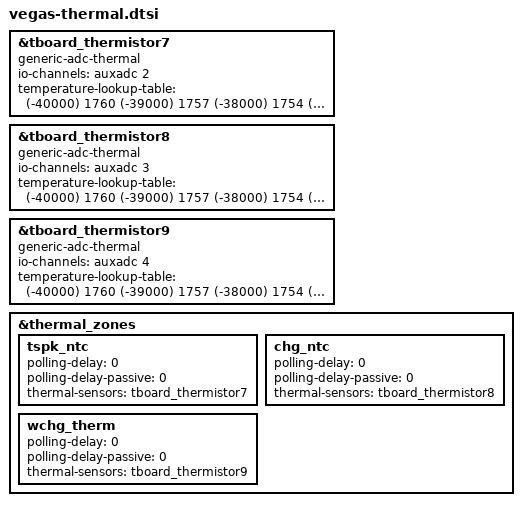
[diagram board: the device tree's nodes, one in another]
#include <dt-bindings/iio/mt635x-auxadc.h>

	&tboard_thermistor7 {
		compatible = "generic-adc-thermal";
		#thermal-sensor-cells = <0>;
		io-channels = <&auxadc 2>;
		io-channel-names = "sensor-channel";
		temperature-lookup-table = <
			(-40000) 1760
			(-39000) 1757
			(-38000) 1754
			(-37000) 1751
			(-36000) 1747
			(-35000) 1744
			(-34000) 1740
			(-33000) 1736
			(-32000) 1731
			(-31000) 1727
			(-30000) 1722
			(-29000) 1716
			(-28000) 1711
			(-27000) 1705
			(-26000) 1699
			(-25000) 1693
			(-24000) 1686
			(-23000) 1679
			(-22000) 1672
			(-21000) 1664
			(-20000) 1656
			(-19000) 1648
			(-18000) 1639
			(-17000) 1630
			(-16000) 1620
			(-15000) 1610
			(-14000) 1599
			(-13000) 1588
			(-12000) 1577
			(-11000) 1565
			(-10000) 1553
			(-9000) 1540
			(-8000) 1527
			(-7000) 1514
			(-6000) 1500
			(-5000) 1485
			(-4000) 1470
			(-3000) 1455
			(-2000) 1439
			(-1000) 1423
			0 1406
			1000 1389
			2000 1372
			3000 1354
			4000 1335
			5000 1317
			6000 1298
			7000 1279
			8000 1259
			9000 1239
			10000 1219
			11000 1198
			12000 1178
			13000 1157
			14000 1136
			15000 1115
			16000 1093
			17000 1072
			18000 1050
			19000 1029
			20000 1007
			21000 986
			22000 964
			23000 943
			24000 921
			25000 900
			26000 879
			27000 858
			28000 837
			29000 816
			30000 796
			31000 775
			32000 755
			33000 736
			34000 716
			35000 697
			36000 678
			37000 659
			38000 641
			39000 623
			40000 605
			41000 588
			42000 571
			43000 555
			44000 538
			45000 523
			46000 507
			47000 492
			48000 477
			49000 463
			50000 449
			51000 435
			52000 422
			53000 409
			54000 396
			55000 384
			56000 372
			57000 360
			58000 349
			59000 338
			60000 327
			61000 317
			62000 307
			63000 297
			64000 288
			65000 279
			66000 270
			67000 261
			68000 253
			69000 245
			70000 237
			71000 230
			72000 222
			73000 215
			74000 209
			75000 202
			76000 196
			77000 189
			78000 183
			79000 178
			80000 172
			81000 167
			82000 161
			83000 156
			84000 151
			85000 147
			86000 142
			87000 138
			88000 133
			89000 129
			90000 125
			91000 121
			92000 118
			93000 114
			94000 111
			95000 107
			96000 104
			97000 101
			98000 98
			99000 95
			100000 92
			101000 89
			102000 87
			103000 84
			104000 81
			105000 79
			106000 77
			107000 74
			108000 72
			109000 70
			110000 68
			111000 66
			112000 64
			113000 62
			114000 61
			115000 59
			116000 57
			117000 56
			118000 54
			119000 52
			120000 51
			121000 50
			122000 48
			123000 47
			124000 46
			125000 44>;
	};

	&tboard_thermistor8 {
		compatible = "generic-adc-thermal";
		#thermal-sensor-cells = <0>;
		io-channels = <&auxadc 3>;
		io-channel-names = "sensor-channel";
		temperature-lookup-table = <
			(-40000) 1760
			(-39000) 1757
			(-38000) 1754
			(-37000) 1751
			(-36000) 1747
			(-35000) 1744
			(-34000) 1740
			(-33000) 1736
			(-32000) 1731
			(-31000) 1727
			(-30000) 1722
			(-29000) 1716
			(-28000) 1711
			(-27000) 1705
			(-26000) 1699
			(-25000) 1693
			(-24000) 1686
			(-23000) 1679
			(-22000) 1672
			(-21000) 1664
			(-20000) 1656
			(-19000) 1648
			(-18000) 1639
			(-17000) 1630
			(-16000) 1620
			(-15000) 1610
			(-14000) 1599
			(-13000) 1588
			(-12000) 1577
			(-11000) 1565
			(-10000) 1553
			(-9000) 1540
			(-8000) 1527
			(-7000) 1514
			(-6000) 1500
			(-5000) 1485
			(-4000) 1470
			(-3000) 1455
			(-2000) 1439
			(-1000) 1423
			0 1406
			1000 1389
			2000 1372
			3000 1354
			4000 1335
			5000 1317
			6000 1298
			7000 1279
			8000 1259
			9000 1239
			10000 1219
			11000 1198
			12000 1178
			13000 1157
			14000 1136
			15000 1115
			16000 1093
			17000 1072
			18000 1050
			19000 1029
			20000 1007
			21000 986
			22000 964
			23000 943
			24000 921
			25000 900
			26000 879
			27000 858
			28000 837
			29000 816
			30000 796
			31000 775
			32000 755
			33000 736
			34000 716
			35000 697
			36000 678
			37000 659
			38000 641
			39000 623
			40000 605
			41000 588
			42000 571
			43000 555
			44000 538
			45000 523
			46000 507
			47000 492
			48000 477
			49000 463
			50000 449
			51000 435
			52000 422
			53000 409
			54000 396
			55000 384
			56000 372
			57000 360
			58000 349
			59000 338
			60000 327
			61000 317
			62000 307
			63000 297
			64000 288
			65000 279
			66000 270
			67000 261
			68000 253
			69000 245
			70000 237
			71000 230
			72000 222
			73000 215
			74000 209
			75000 202
			76000 196
			77000 189
			78000 183
			79000 178
			80000 172
			81000 167
			82000 161
			83000 156
			84000 151
			85000 147
			86000 142
			87000 138
			88000 133
			89000 129
			90000 125
			91000 121
			92000 118
			93000 114
			94000 111
			95000 107
			96000 104
			97000 101
			98000 98
			99000 95
			100000 92
			101000 89
			102000 87
			103000 84
			104000 81
			105000 79
			106000 77
			107000 74
			108000 72
			109000 70
			110000 68
			111000 66
			112000 64
			113000 62
			114000 61
			115000 59
			116000 57
			117000 56
			118000 54
			119000 52
			120000 51
			121000 50
			122000 48
			123000 47
			124000 46
			125000 44>;
	};

	&tboard_thermistor9 {
		compatible = "generic-adc-thermal";
		#thermal-sensor-cells = <0>;
		io-channels = <&auxadc 4>;
		io-channel-names = "sensor-channel";
		temperature-lookup-table = <
			(-40000) 1760
			(-39000) 1757
			(-38000) 1754
			(-37000) 1751
			(-36000) 1747
			(-35000) 1744
			(-34000) 1740
			(-33000) 1736
			(-32000) 1731
			(-31000) 1727
			(-30000) 1722
			(-29000) 1716
			(-28000) 1711
			(-27000) 1705
			(-26000) 1699
			(-25000) 1693
			(-24000) 1686
			(-23000) 1679
			(-22000) 1672
			(-21000) 1664
			(-20000) 1656
			(-19000) 1648
			(-18000) 1639
			(-17000) 1630
			(-16000) 1620
			(-15000) 1610
			(-14000) 1599
			(-13000) 1588
			(-12000) 1577
			(-11000) 1565
			(-10000) 1553
			(-9000) 1540
			(-8000) 1527
			(-7000) 1514
			(-6000) 1500
			(-5000) 1485
			(-4000) 1470
			(-3000) 1455
			(-2000) 1439
			(-1000) 1423
			0 1406
			1000 1389
			2000 1372
			3000 1354
			4000 1335
			5000 1317
			6000 1298
			7000 1279
			8000 1259
			9000 1239
			10000 1219
			11000 1198
			12000 1178
			13000 1157
			14000 1136
			15000 1115
			16000 1093
			17000 1072
			18000 1050
			19000 1029
			20000 1007
			21000 986
			22000 964
			23000 943
			24000 921
			25000 900
			26000 879
			27000 858
			28000 837
			29000 816
			30000 796
			31000 775
			32000 755
			33000 736
			34000 716
			35000 697
			36000 678
			37000 659
			38000 641
			39000 623
			40000 605
			41000 588
			42000 571
			43000 555
			44000 538
			45000 523
			46000 507
			47000 492
			48000 477
			49000 463
			50000 449
			51000 435
			52000 422
			53000 409
			54000 396
			55000 384
			56000 372
			57000 360
			58000 349
			59000 338
			60000 327
			61000 317
			62000 307
			63000 297
			64000 288
			65000 279
			66000 270
			67000 261
			68000 253
			69000 245
			70000 237
			71000 230
			72000 222
			73000 215
			74000 209
			75000 202
			76000 196
			77000 189
			78000 183
			79000 178
			80000 172
			81000 167
			82000 161
			83000 156
			84000 151
			85000 147
			86000 142
			87000 138
			88000 133
			89000 129
			90000 125
			91000 121
			92000 118
			93000 114
			94000 111
			95000 107
			96000 104
			97000 101
			98000 98
			99000 95
			100000 92
			101000 89
			102000 87
			103000 84
			104000 81
			105000 79
			106000 77
			107000 74
			108000 72
			109000 70
			110000 68
			111000 66
			112000 64
			113000 62
			114000 61
			115000 59
			116000 57
			117000 56
			118000 54
			119000 52
			120000 51
			121000 50
			122000 48
			123000 47
			124000 46
			125000 44>;
	};
&thermal_zones
{
	tspk_ntc: tspk_ntc {
		polling-delay = <0>; /* milliseconds */
		polling-delay-passive = <0>; /* milliseconds */
		thermal-sensors = <&tboard_thermistor7>;
	};
	chg_ntc: chg_ntc {
		polling-delay = <0>; /* milliseconds */
		polling-delay-passive = <0>; /* milliseconds */
		thermal-sensors = <&tboard_thermistor8>;
	};
	wchg_therm: wchg_therm {
		polling-delay = <0>; /* milliseconds */
		polling-delay-passive = <0>; /* milliseconds */
		thermal-sensors = <&tboard_thermistor9>;
	};
};
